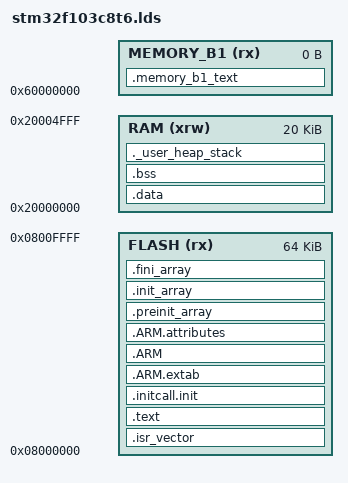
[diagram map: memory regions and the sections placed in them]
ENTRY(Reset_Handler)
_estack = 0x20005000;
_Min_Heap_Size = 0;
_Min_Stack_Size = 0x100;
MEMORY
{
  FLASH (rx) : ORIGIN = 0x08000000, LENGTH = 64K
  RAM (xrw) : ORIGIN = 0x20000000, LENGTH = 20K
  MEMORY_B1 (rx) : ORIGIN = 0x60000000, LENGTH = 0K
}
SECTIONS
{
  .isr_vector :
  {
    . = ALIGN(4);
    KEEP(*(.isr_vector))
    . = ALIGN(4);
  } >FLASH
  .text :
  {
    . = ALIGN(4);
    *(.text)
    *(.text*)
    *(.rodata)
    *(.rodata*)
    *(.glue_7)
    *(.glue_7t)
    . = ALIGN(4);
    _etext = .;
  } >FLASH
   . = ALIGN(4);
   .initcall.init :
   {
     __initcall_start = .; KEEP(*(.initcallearly.init)) __initcall0_start = .; KEEP(*(.initcall0.init)) KEEP(*(.initcall0s.init)) __initcall1_start = .; KEEP(*(.initcall1.init)) KEEP(*(.initcall1s.init)) __initcall2_start = .; KEEP(*(.initcall2.init)) KEEP(*(.initcall2s.init)) __initcall3_start = .; KEEP(*(.initcall3.init)) KEEP(*(.initcall3s.init)) __initcall4_start = .; KEEP(*(.initcall4.init)) KEEP(*(.initcall4s.init)) __initcall5_start = .; KEEP(*(.initcall5.init)) KEEP(*(.initcall5s.init)) __initcallrootfs_start = .; KEEP(*(.initcallrootfs.init)) KEEP(*(.initcallrootfss.init)) __initcall6_start = .; KEEP(*(.initcall6.init)) KEEP(*(.initcall6s.init)) __initcall7_start = .; KEEP(*(.initcall7.init)) KEEP(*(.initcall7s.init)) __initcall_end = .;
   } >FLASH
   .ARM.extab : { *(.ARM.extab* .gnu.linkonce.armextab.*) } >FLASH
    .ARM : {
    __exidx_start = .;
      *(.ARM.exidx*)
      __exidx_end = .;
    } >FLASH
  .ARM.attributes : { *(.ARM.attributes) } > FLASH
  .preinit_array :
  {
    PROVIDE_HIDDEN (__preinit_array_start = .);
    KEEP (*(.preinit_array*))
    PROVIDE_HIDDEN (__preinit_array_end = .);
  } >FLASH
  .init_array :
  {
    PROVIDE_HIDDEN (__init_array_start = .);
    KEEP (*(SORT(.init_array.*)))
    KEEP (*(.init_array*))
    PROVIDE_HIDDEN (__init_array_end = .);
  } >FLASH
  .fini_array :
  {
    PROVIDE_HIDDEN (__fini_array_start = .);
    KEEP (*(.fini_array*))
    KEEP (*(SORT(.fini_array.*)))
    PROVIDE_HIDDEN (__fini_array_end = .);
  } >FLASH
  _sidata = .;
  .data : AT ( _sidata )
  {
    . = ALIGN(4);
    _sdata = .;
    *(.data)
    *(.data*)
    . = ALIGN(4);
    _edata = .;
  } >RAM
  . = ALIGN(4);
  .bss :
  {
    _sbss = .;
    __bss_start__ = _sbss;
    *(.bss)
    *(.bss*)
    *(COMMON)
    . = ALIGN(4);
    _ebss = .;
    __bss_end__ = _ebss;
  } >RAM
  PROVIDE ( end = _ebss );
  PROVIDE ( _end = _ebss );
  ._user_heap_stack :
  {
    . = ALIGN(4);
    . = . + _Min_Heap_Size;
    . = . + _Min_Stack_Size;
    . = ALIGN(4);
  } >RAM
  .memory_b1_text :
  {
    *(.mb1text)
    *(.mb1text*)
    *(.mb1rodata)
    *(.mb1rodata*)
  } >MEMORY_B1
  /DISCARD/ :
  {
    libc.a ( * )
    libm.a ( * )
    libgcc.a ( * )
  }
}
